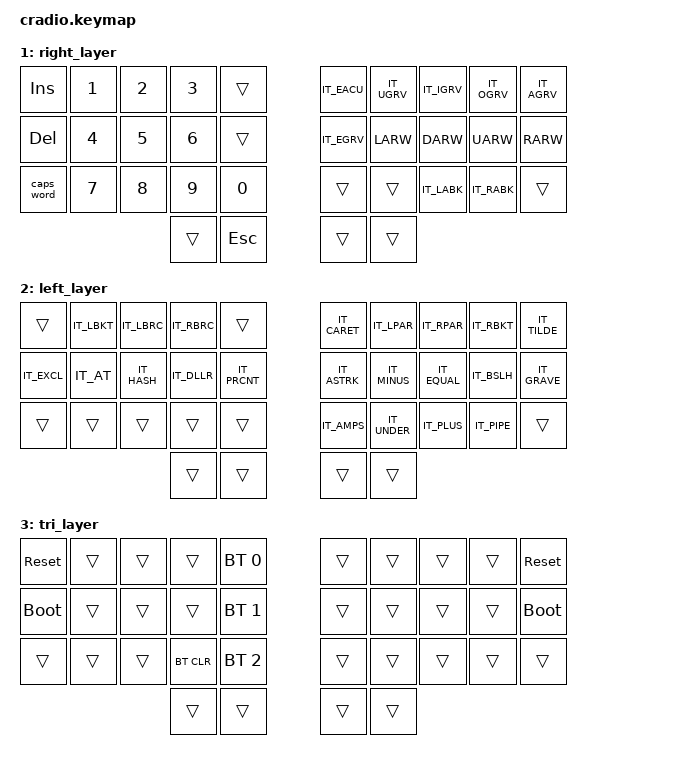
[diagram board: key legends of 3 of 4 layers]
// Copyright (c) 2022 The ZMK Contributors
// SPDX-License-Identifier: MIT

#include <behaviors.dtsi>
#include <dt-bindings/zmk/keys.h>
#include <dt-bindings/zmk/bt.h>
#include <italian.h>

// Home row mods macro
#define HRML(k1,k2,k3,k4) &ht LSHFT k1  &ht LALT k2  &ht LCTRL k3  &ht LGUI k4
#define HRMR(k1,k2,k3,k4) &ht RGUI k1  &ht RCTRL k2  &ht RALT k3  &ht RSHFT k4

/ {
    behaviors {
        ht: hold_tap {
            label = "hold_tap";
            compatible = "zmk,behavior-hold-tap";
            #binding-cells = <2>;
            flavor = "tap-preferred";
            tapping-term-ms = <220>;
            quick-tap-ms = <150>;
            global-quick-tap;
            bindings = <&kp>, <&kp>;
        };
    };

    conditional_layers {
        compatible = "zmk,conditional-layers";
        tri_layer {
            if-layers = <1 2>;
            then-layer = <3>;
        };
    };

    keymap {
        compatible = "zmk,keymap";
        default_layer {
            bindings = <
        //╭──────────┬──────────┬──────────┬──────────┬──────────╮   ╭──────────┬──────────┬──────────┬──────────┬──────────╮
        //│  Q       │  W       │  E       │  R       │  T       │   │  Y       │  U       │  I       │  O       │  P       │
            &kp Q      &kp W      &kp E      &kp R      &kp T          &kp Y      &kp U      &kp I      &kp O      &kp P
        //├──────────┼──────────┼──────────┼──────────┼──────────┤   ├──────────┼──────────┼──────────┼──────────┼──────────┤
        //│  A       │  S       │  D       │  F       │  G       │   │  H       │  J       │  K       │  L       │ ' "      │
            HRML(A,        S,         D,         F)     &kp G          &kp H      HRMR(J,        K,         L,        IT_QUOT)
        //├──────────┼──────────┼──────────┼──────────┼──────────┤   ├──────────┼──────────┼──────────┼──────────┼──────────┤
        //│  Z       │  X       │  C       │  V       │  B       │   │  N       │  M       │ , <      │ . >      │ / ?      │
            &kp Z      &kp X      &kp C      &kp V      &kp B          &kp N      &kp M      &kp IT_COMM  &kp IT_DOT    &kp IT_SLSH
        //╰──────────┴──────────┴──────────┼──────────┼──────────┤   ├──────────┼──────────┼──────────┴──────────┴──────────╯
                                            &lt 2 TAB   &kp ENTER     &kp SPACE  &lt 1 BSPC
        //                                 ╰──────────┴──────────╯   ╰──────────┴──────────╯
            >;
        };

        right_layer {
            bindings = <
        //╭──────────┬──────────┬──────────┬──────────┬──────────╮   ╭──────────┬──────────┬──────────┬──────────┬──────────╮
        //│ INSERT   │  1       │  2       │  3       │          │   │    é     │    ù     │    ì     │    ò     │    à     │
            &kp INS    &kp N1     &kp N2     &kp N3     &trans         &kp IT_EACU &kp IT_UGRV &kp IT_IGRV &kp IT_OGRV &kp IT_AGRV
        //├──────────┼──────────┼──────────┼──────────┼──────────┤   ├──────────┼──────────┼──────────┼──────────┼──────────┤
        //│ DELETE   │  4       │  5       │  6       │          │   │    è     │   LEFT   │   DOWN   │   UP     │   RIGHT  │
            &kp DEL    &kp N4     &kp N5     &kp N6     &trans         &kp IT_EGRV &kp LARW    &kp DARW    &kp UARW    &kp RARW
        //├──────────┼──────────┼──────────┼──────────┼──────────┤   ├──────────┼──────────┼──────────┼──────────┼──────────┤
        //│ CAPS     │  7       │  8       │  9       │  0       │   │          │          │          │          │          │
           &caps_word  &kp N7     &kp N8     &kp N9     &kp N0         &trans     &trans     &kp IT_LABK    &kp IT_RABK     &trans
        //╰──────────┴──────────┴──────────┼──────────┼──────────┤   ├──────────┼──────────┼──────────┴──────────┴──────────╯
                                             &trans     &kp ESC        &trans     &trans
        //                                 ╰──────────┴──────────╯   ╰──────────┴──────────╯
            >;
        };

        left_layer {
            bindings = <
        //╭──────────┬──────────┬──────────┬──────────┬──────────╮   ╭──────────┬──────────┬──────────┬──────────┬──────────╮
        //│          │  [       │  {       │  }       │          │   │  ^       │  (       │  )       │  ]       │  ~       │
            &trans     &kp IT_LBKT   &kp IT_LBRC   &kp IT_RBRC   &trans         &kp IT_CARET  &kp IT_LPAR   &kp IT_RPAR   &kp IT_RBKT   &kp IT_TILDE
        //├──────────┼──────────┼──────────┼──────────┼──────────┤   ├──────────┼──────────┼──────────┼──────────┼──────────┤
        //│  !       │  @       │  #       │  $       │  %       │   │  *       │  -       │  =       │  \       │  `       │
            &kp IT_EXCL   &kp IT_AT     &kp IT_HASH   &kp IT_DLLR   &kp IT_PRCNT      &kp IT_ASTRK  &kp IT_MINUS  &kp IT_EQUAL  &kp IT_BSLH   &kp IT_GRAVE
        //├──────────┼──────────┼──────────┼──────────┼──────────┤   ├──────────┼──────────┼──────────┼──────────┼──────────┤
        //│          │          │          │          │          │   │  &       │  _       │  +       │  │       │          │
            &trans     &trans     &trans     &trans     &trans         &kp IT_AMPS   &kp IT_UNDER  &kp IT_PLUS   &kp IT_PIPE   &trans
        //╰──────────┴──────────┴──────────┼──────────┼──────────┤   ├──────────┼──────────┼──────────┴──────────┴──────────╯
                                             &trans     &trans         &trans     &trans
        //                                 ╰──────────┴──────────╯   ╰──────────┴──────────╯
            >;
        };

        tri_layer {
            bindings = <
        //╭──────────┬──────────┬──────────┬──────────┬──────────╮   ╭──────────┬──────────┬──────────┬──────────┬──────────╮
        //│ RESET    │          │          │          │PROFILE 0 │   │          │          │          │          │  RESET   │
           &sys_reset  &trans     &trans     &trans    &bt BT_SEL 0    &trans     &trans     &trans     &trans    &sys_reset
        //├──────────┼──────────┼──────────┼──────────┼──────────┤   ├──────────┼──────────┼──────────┼──────────┼──────────┤
        //│BOOTLOADER│          │          │          │PROFILE 1 │   │          │          │          │          │BOOTLOADER│
          &bootloader  &trans     &trans     &trans    &bt BT_SEL 1    &trans     &trans     &trans     &trans    &bootloader
        //├──────────┼──────────┼──────────┼──────────┼──────────┤   ├──────────┼──────────┼──────────┼──────────┼──────────┤
        //│          │          │          │ CLEAR BT │PROFILE 2 │   │          │          │          │          │          │
            &trans     &trans     &trans    &bt BT_CLR &bt BT_SEL 2    &trans     &trans     &trans     &trans     &trans
        //╰──────────┴──────────┴──────────┼──────────┼──────────┤   ├──────────┼──────────┼──────────┴──────────┴──────────╯
                                             &trans     &trans         &trans     &trans
        //                                 ╰──────────┴──────────╯   ╰──────────┴──────────╯
            >;
        };
    };
};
